# DA14580 register map
Vendor: Dialog; Series: DA14580x; File version: 1.2
CPU: CM0 r1p0, little endian, MPU, FPU, 3 interrupt priority bits
Registers are 16-bit, read-write, reset 0x0 unless marked. A register's access mark holds for its fields unless they carry their own. Offsets are from the block's base; [hi:lo] are bit positions.

## SysTick — Cortex M0 SysTick registers
Base 0xE000E010
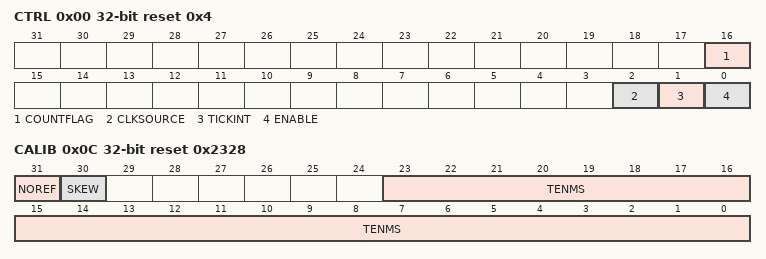
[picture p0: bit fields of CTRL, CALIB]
0x00 CTRL 32-bit reset 0x4 — SysTick Control and Status register
  [16] COUNTFLAG — Timer counted to 0 since last time this was read
  [2] CLKSOURCE — Clock source selection
  [1] TICKINT — SysTick exception request enable
  [0] ENABLE — SysTick Counter enable
0x04 LOAD 32-bit — SysTick Reload value register
  [23:0] RELOAD — RELOAD[23:0] bits (Reload value)
0x08 VAL 32-bit — SysTick Current value register
  [23:0] CURRENT — CURRENT[23:0] bits (Current counter value)
0x0C CALIB 32-bit ro reset 0x2328 — SysTick Calibration value register
  [31] NOREF — Indicates that a separate reference clock is provided
  [30] SKEW — Indicates whether the TENMS value is exact
  [23:0] TENMS — TENMS[23:0] bits (Calibration value)

## anamisc580_nl01 — anamisc580_nl01 registers
Base 0x50001600
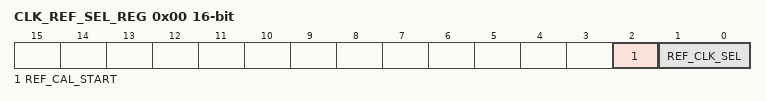
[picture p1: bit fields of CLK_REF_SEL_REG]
0x00 CLK_REF_SEL_REG — Select clock for oscillator calibration
  [2] REF_CAL_START — Writing a '1' starts a calibration. This bit is cleared when calibration is finished, and CLK_REF_VAL is ready.
  [1:0] REF_CLK_SEL — Select clock input for calibration: 0x0 : RC32K oscillator 0x1 : RC16M oscillator 0x2 : XTAL32K oscillator 0x3 : RCX oscillator
0x02 CLK_REF_CNT_REG — Count value for oscillator calibration
  [15:0] REF_CNT_VAL — Indicates the calibration time, with a decrement counter to 1.
0x04 CLK_REF_VAL_L_REG — XTAL16M reference cycles, lower 16 bits
  [15:0] XTAL_CNT_VAL ro — Returns the lower 16 bits of XTAL16 clock cycles during the calibration time, defined with REF_CNT_VAL
0x06 CLK_REF_VAL_H_REG — XTAL16M reference cycles, upper 16 bits
  [15:0] XTAL_CNT_VAL ro — Returns the upper 16 bits of XTAL16 clock cycles during the calibration time, defined with REF_CNT_VAL

## CHIP_VERSION — CHIP_VERSION registers
Base 0x50003200
0x00 CHIP_ID1_REG 8-bit reset 0x35 — Chip identification register 1.
  [7:0] CHIP_ID1 ro — First character of device type '580' in ASCII.
0x01 CHIP_ID2_REG 8-bit reset 0x38 — Chip identification register 2.
  [7:0] CHIP_ID2 ro — Second character of device type '580' in ASCII.
0x02 CHIP_ID3_REG 8-bit reset 0x30 — Chip identification register 3.
  [7:0] CHIP_ID3 ro — Third character of device type '580' in ASCII.
0x03 CHIP_SWC_REG 8-bit — Software compatibility register.
  [3:0] CHIP_SWC ro — SoftWare Compatibility code. Integer (default = 0) which is incremented if a silicon change has impact on the CPU Firmware. Can be used by software developers to write silicon revision dependent code.
0x04 CHIP_REVISION_REG 8-bit reset 0x41 — Chip revision register.
  [7:0] REVISION_ID ro — Chip version, corresponds with type number in ASCII. 0x41 = 'A', 0x42 = 'B'

## crg580_dcdc_nl01 — crg580_dcdc_nl01 registers
Base 0x50000080
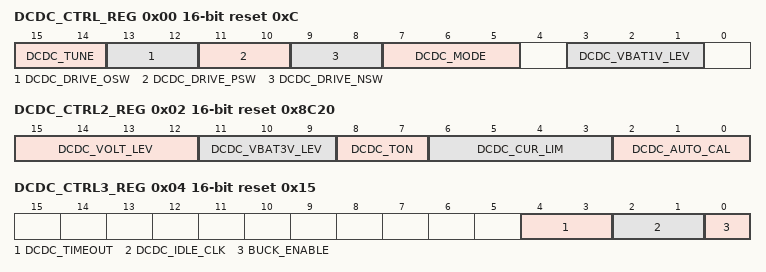
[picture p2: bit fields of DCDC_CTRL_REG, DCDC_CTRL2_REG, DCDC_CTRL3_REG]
0x00 DCDC_CTRL_REG reset 0xC — DCDC control register
  [15:14] DCDC_TUNE — Tune-bits to compensate for parasitic resistance in the current sense circuit of the DCDC-converter.
  [13:12] DCDC_DRIVE_OSW — Drive level of the switch between SWITCH and VDCDC. 00 = 100 percent 01 = 66 percent 10 = 33 percent 11 = off
  [11:10] DCDC_DRIVE_PSW — Drive level of the switch between SWITCH and VBAT3V. 00 = 100 percent 01 = 66 percent 10 = 33 percent 11 = off
  [9:8] DCDC_DRIVE_NSW — Drive level of the switch between SWITCH and GROUND. 00 = 100 percent 01 = 66 percent 10 = 33 percent 11 = off
  [7:5] DCDC_MODE — Testmodes, keep 000.
  [3:1] DCDC_VBAT1V_LEV — If VBAT1V is below this level, the boost converter will be disabled: 110 = 0.6V 101 = 0.8V 011 = 1.0V 111 = 0V (always OK)
0x02 DCDC_CTRL2_REG reset 0x8C20 — DCDC second control register
  [15:12] DCDC_VOLT_LEV — Nominal output voltage of the DCDC-converter. VDCDC = 1.2V + N*25mV
  [11:9] DCDC_VBAT3V_LEV — Nominal VBAT3V output voltage of the boost converter. 000 ... 011 = 1.8V + N*25mV 100 = 2.4V 101 = 2.5V 110 = 2.62V 111 = 2.76V (Note: MSB is automatically on if the OTP LDO is enabled.)
  [8:7] DCDC_TON — This defines the minimum on-time of the comparators. For buck-mode use 0x2, for boost-mode use 0x1
  [6:3] DCDC_CUR_LIM — Current limit in the switches of the DCDC-converter (approximate values): N x 10mA
  [2:0] DCDC_AUTO_CAL — Control of the automatic calibration of the DCDC-converter. For Buck-mode use 0x1, for Boost-mode use 0x6. Automatic calibration is disabled by setting 0x0
0x04 DCDC_CTRL3_REG reset 0x15 — DCDC thirth control register
  [4:3] DCDC_TIMEOUT — timeout for the idle state to check voltage
  [2:1] DCDC_IDLE_CLK — Clock used as trigger for the idle state to check voltage. (Note: when no 16 MHz oscillator is active, the 32 kHz oscillator will be used as trigger independent of the setting below:) 00 = 16 MHz 01 = 4 MHz 10 = 1 MHz 11 = 250 kHz
  [0] BUCK_ENABLE — Enables the buck converter when the device becomes active and VBAT1V is connected to GND.
